# CPSW1_NUSS register map
Vendor: Texas Instruments
Registers are 32-bit, read-write, reset 0x0 unless marked. A register's access mark holds for its fields unless they carry their own. Offsets are as the file gives them; [hi:lo] are bit positions; lines under a group give offsets from that group; {n}, {i} and the like mark numbered series; <NAME> marks a mode.

## CPSW1_NUSS (part 2 of 2)
0x3A2BC CPSW_NUSS_VBUSP_ALE_UNKN_BRD_BCNT — ALE Receive Unknown Broadcast Bytecount
  [31:0] COUNT
0x3A2C0 CPSW_NUSS_VBUSP_ALE_POL_MATCH — ALE Policer Matched
  [31:0] COUNT
0x3A2C4 CPSW_NUSS_VBUSP_ALE_POL_MATCH_RED — ALE Policer Matched and Condition Red
  [31:0] COUNT
0x3A2C8 CPSW_NUSS_VBUSP_ALE_POL_MATCH_YELLOW — ALE Policer Matched and Condition Yellow
  [31:0] COUNT
0x3A2CC CPSW_NUSS_VBUSP_ALE_MULT_SA_DROP — ALE Multicast Source Address Drop
  [31:0] COUNT — ALE Multicast Source Address drop
0x3A2D0 CPSW_NUSS_VBUSP_ALE_DUAL_VLAN_DROP — ALE Dual VLAN Drop
  [31:0] COUNT — ALE Dual VLAN drop
0x3A2D4 CPSW_NUSS_VBUSP_ALE_LEN_ERROR_DROP — ALE Length Error Drop
  [31:0] COUNT — ALE Length Error drop
0x3A2D8 CPSW_NUSS_VBUSP_ALE_IP_NEXT_HDR_DROP — ALE IP Next Header Drop
  [31:0] COUNT — ALE Next Header drop
0x3A2DC CPSW_NUSS_VBUSP_ALE_IPV4_FRAG_DROP — ALE IPV4 Frag Drop
  [31:0] COUNT — ALE IPV4 Fragment drop
0x3A340 CPSW_NUSS_VBUSP_IET_RX_ASSEMBLY_ERROR_REG — IET Receive Assembly Error
  [31:0] IET_RX_ASSEMBLY_ERROR
0x3A344 CPSW_NUSS_VBUSP_IET_RX_ASSEMBLY_OK_REG — IET Receive Assembly Ok
  [31:0] IET_RX_ASSEMBLY_OK
0x3A348 CPSW_NUSS_VBUSP_IET_RX_SMD_ERROR_REG — IET Receive Smd Error
  [31:0] IET_RX_SMD_ERROR
0x3A34C CPSW_NUSS_VBUSP_IET_RX_FRAG_REG — IET Receive Frag
  [31:0] IET_RX_FRAG
0x3A350 CPSW_NUSS_VBUSP_IET_TX_HOLD_REG — IET Transmit Hold
  [31:0] IET_TX_HOLD
0x3A354 CPSW_NUSS_VBUSP_IET_TX_FRAG_REG — IET Transmit Frag
  [31:0] IET_TX_FRAG
0x3A37C CPSW_NUSS_VBUSP_TX_MEMORY_PROTECT_ERROR — Transmit Memory Protect CRC Error
  [7:0] COUNT
0x3A380 CPSW_NUSS_VBUSP_ENET_PN_TX_PRI_REG — ENET Port n PRIORITY N Packet Count
  [31:0] PN_TX_PRIN — Enet Port n Priority N Packet Count
0x3A3A0 CPSW_NUSS_VBUSP_ENET_PN_TX_PRI_BCNT_REG — ENET Port n PRIORITY N Packet Byte Count
  [31:0] PN_TX_PRIN_BCNT
0x3A3C0 CPSW_NUSS_VBUSP_ENET_PN_TX_PRI_DROP_REG — ENET Port n PRIORITY N Packet Drop Count
  [31:0] PN_TX_PRIN_DROP
0x3A3E0 CPSW_NUSS_VBUSP_ENET_PN_TX_PRI_DROP_BCNT_REG — ENET Port n PRIORITY N Packet Drop Byte Count
  [31:0] PN_TX_PRIN_DROP_BCNT
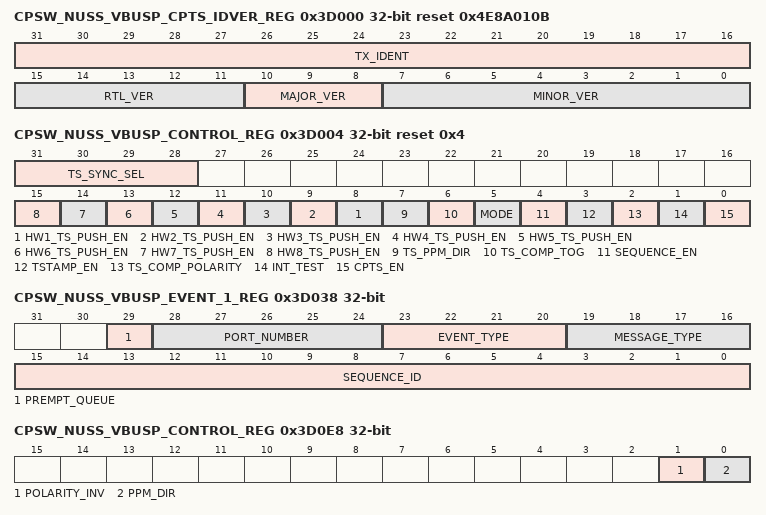
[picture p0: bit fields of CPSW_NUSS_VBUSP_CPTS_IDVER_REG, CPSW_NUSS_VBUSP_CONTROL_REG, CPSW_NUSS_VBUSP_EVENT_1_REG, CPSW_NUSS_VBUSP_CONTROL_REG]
0x3D000 CPSW_NUSS_VBUSP_CPTS_IDVER_REG ro reset 0x4E8A010B — Identification and Version Register
  [31:16] TX_IDENT — Identification value
  [15:11] RTL_VER — RTL version value
  [10:8] MAJOR_VER — Major version value
  [7:0] MINOR_VER — Minor version value
0x3D004 CPSW_NUSS_VBUSP_CONTROL_REG reset 0x4 — Time Sync Control Register
  [31:28] TS_SYNC_SEL — TS_SYNC output timestamp counter bit select
  [n+7] HW{n}_TS_PUSH_EN (n=1..8) — Hardware push {n} enable
  [7] TS_PPM_DIR — Timestamp PPM Direction
  [6] TS_COMP_TOG — Timestamp Compare Toggle mode: 0=TS_COMP is in non-toggle mode, 1=TS_COMP is in toggle mode
  [5] MODE — Timestamp mode
  [4] SEQUENCE_EN — Sequence Enable
  [3] TSTAMP_EN — Host Receive Timestamp Enable
  [2] TS_COMP_POLARITY
  [1] INT_TEST — Interrupt test
  [0] CPTS_EN — Time sync enable
0x3D008 CPSW_NUSS_VBUSP_RFTCLK_SEL_REG — RFTCLK Select Register
  [4:0] RFTCLK_SEL — Reference clock select
0x3D00C CPSW_NUSS_VBUSP_TS_PUSH_REG wo — Time Stamp Event Push Register
  [0] TS_PUSH — Time stamp event push
0x3D010 CPSW_NUSS_VBUSP_TS_LOAD_LOW_VAL_REG — Time Stamp Load Low Value Register
  [31:0] TS_LOAD_VAL — Time stamp load low value
0x3D014 CPSW_NUSS_VBUSP_TS_LOAD_EN_REG wo — Time Stamp Load Enable Register
  [0] TS_LOAD_EN — Time stamp load enable
0x3D018 CPSW_NUSS_VBUSP_TS_COMP_LOW_VAL_REG — Time Stamp Comparison Low Value Register
  [31:0] TS_COMP_VAL — Time stamp comparison low value
0x3D01C CPSW_NUSS_VBUSP_TS_COMP_LEN_REG — Time Stamp Comparison Length Register
  [31:0] TS_COMP_LENGTH — Time stamp comparison length
0x3D020 CPSW_NUSS_VBUSP_INTSTAT_RAW_REG — Interrupt Status Register Raw
  [0] TS_PEND_RAW — TS_PEND_RAW int read (before enable)
0x3D024 CPSW_NUSS_VBUSP_INTSTAT_MASKED_REG ro — Interrupt Status Register Masked
  [0] TS_PEND — TS_PEND masked interrupt read (after enable)
0x3D028 CPSW_NUSS_VBUSP_INT_ENABLE_REG — Interrupt Enable Register
  [0] TS_PEND_EN — TS_PEND masked interrupt enable
0x3D02C CPSW_NUSS_VBUSP_TS_COMP_NUDGE_REG — Time Stamp Comparison Nudge Register
  [7:0] NUDGE — This 2s complement number is added to the ts_comp_length value to increase or decrease the TS_COMP length by the nudge amount
0x3D030 CPSW_NUSS_VBUSP_EVENT_POP_REG wo — Event Pop Register
  [0] EVENT_POP
0x3D034 CPSW_NUSS_VBUSP_EVENT_0_REG ro — Event 0 Register
  [31:0] TIME_STAMP
0x3D038 CPSW_NUSS_VBUSP_EVENT_1_REG ro — Event 1 Register
  [29] PREMPT_QUEUE, [28:24] PORT_NUMBER, [23:20] EVENT_TYPE, [19:16] MESSAGE_TYPE, [15:0] SEQUENCE_ID
0x3D03C CPSW_NUSS_VBUSP_EVENT_2_REG ro — Event 2 Register
  [7:0] DOMAIN
0x3D040 CPSW_NUSS_VBUSP_EVENT_3_REG ro — Event 3 Register
  [31:0] TIME_STAMP
0x3D044 CPSW_NUSS_VBUSP_TS_LOAD_HIGH_VAL_REG — Time Stamp Load High Value Register
  [31:0] TS_LOAD_VAL — Time stamp load high value
0x3D048 CPSW_NUSS_VBUSP_TS_COMP_HIGH_VAL_REG — Time Stamp Comparison High Value Register
  [31:0] TS_COMP_HIGH_VAL — Time stamp comparison high value
0x3D04C CPSW_NUSS_VBUSP_TS_ADD_VAL_REG — TS Add Value Register
  [2:0] ADD_VAL — Add Value
0x3D050 CPSW_NUSS_VBUSP_TS_PPM_LOW_VAL_REG — Time Stamp PPM Low Value Register
  [31:0] TS_PPM_LOW_VAL — Time stamp PPM Low value
0x3D054 CPSW_NUSS_VBUSP_TS_PPM_HIGH_VAL_REG — Time Stamp PPM High Value Register
  [9:0] TS_PPM_HIGH_VAL — Time stamp PPM High value
0x3D058 CPSW_NUSS_VBUSP_TS_NUDGE_VAL_REG — Time Stamp Nudge Value Register
  [7:0] TS_NUDGE_VAL — Time stamp Nudge value
0x3D0E0 CPSW_NUSS_VBUSP_COMP_LOW_REG — Time Stamp Generate Function Comparison Low Value
  [31:0] COMP_LOW
0x3D0E4 CPSW_NUSS_VBUSP_COMP_HIGH_REG — Time Stamp Generate Function Comparison high Value
  [31:0] COMP_HIGH — Time Stamp Generate Function Comparison High Value
0x3D0E8 CPSW_NUSS_VBUSP_CONTROL_REG — Time Stamp Generate Function Control
  [1] POLARITY_INV — Time Stamp Generate Function Polarity Invert
  [0] PPM_DIR — Time Stamp Generate Function PPM Direction
0x3D0EC CPSW_NUSS_VBUSP_LENGTH_REG — Time Stamp Generate Function Length Value
  [31:0] LENGTH
0x3D0F0 CPSW_NUSS_VBUSP_PPM_LOW_REG — Time Stamp Generate Function PPM Low Value
  [31:0] PPM_LOW
0x3D0F4 CPSW_NUSS_VBUSP_PPM_HIGH_REG — Time Stamp Generate Function PPM High Value
  [9:0] PPM_HIGH
0x3D0F8 CPSW_NUSS_VBUSP_NUDGE_REG — Time Stamp Generate Function Nudge Value
  [7:0] NUDGE
0x3D200 CPSW_NUSS_VBUSP_COMP_LOW_REG — Time Stamp ESTF Generate Function Comparison Low Value
  [31:0] COMP_LOW
0x3D204 CPSW_NUSS_VBUSP_COMP_HIGH_REG — Time Stamp ESTF Generate Function Comparison high Value
  [31:0] COMP_HIGH — Time Stamp ESTF Generate Function Comparison High Value
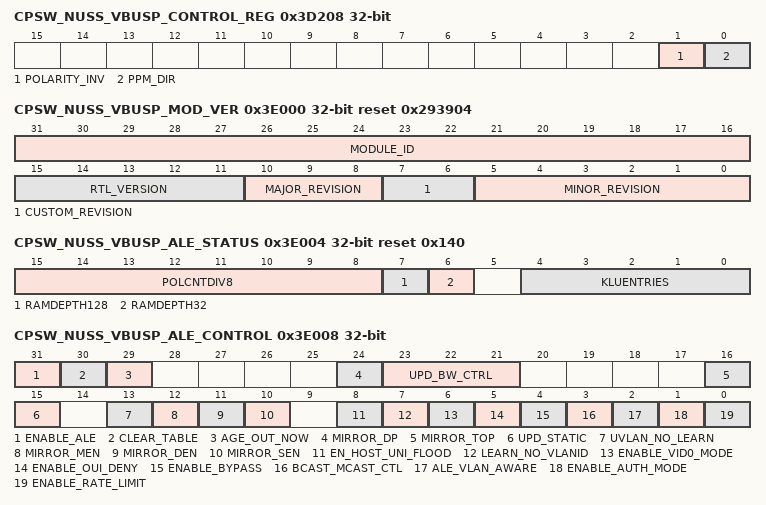
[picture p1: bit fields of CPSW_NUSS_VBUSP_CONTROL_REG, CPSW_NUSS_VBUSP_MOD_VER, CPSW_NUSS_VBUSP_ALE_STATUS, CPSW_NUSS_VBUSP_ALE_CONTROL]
0x3D208 CPSW_NUSS_VBUSP_CONTROL_REG — Time Stamp ESTF Generate Function Control
  [1] POLARITY_INV — Time Stamp ESTF Generate Function Polarity Invert
  [0] PPM_DIR — Time Stamp ESTF Generate Function PPM Direction
0x3D20C CPSW_NUSS_VBUSP_LENGTH_REG — Time Stamp ESTF Generate Function Length Value
  [31:0] LENGTH
0x3D210 CPSW_NUSS_VBUSP_PPM_LOW_REG — Time Stamp ESTF Generate Function PPM Low Value
  [31:0] PPM_LOW
0x3D214 CPSW_NUSS_VBUSP_PPM_HIGH_REG — Time Stamp ESTF Generate Function PPM High Value
  [9:0] PPM_HIGH
0x3D218 CPSW_NUSS_VBUSP_NUDGE_REG — Time Stamp ESTF Generate Function Nudge Value
  [7:0] NUDGE
0x3E000 CPSW_NUSS_VBUSP_MOD_VER ro reset 0x293904 — The Module and Version Register identifies the module identifier and revision of the ALE_2g64i module.
  [31:16] MODULE_ID — ALE_2g64i module ID.
  [15:11] RTL_VERSION
  [10:8] MAJOR_REVISION
  [7:6] CUSTOM_REVISION
  [5:0] MINOR_REVISION
0x3E004 CPSW_NUSS_VBUSP_ALE_STATUS ro reset 0x140 — The ALE status provides information on the ALE configuration and state. The ~iramdepth is used to determine how IPv6 entries are stored in the table. IPv6 entries are stored in two entries where IPv6 Entry hi is designated by the odd slice index and lo is designated by the even slice index. The slice index is above the ram depth like {SlixeIndex,RamIndex}. So for a 64 deep RAM index of 0x005, the Hi portion of the IPv6 entry is located at 0x005|0x040 and the Lo portion is located at 0x005&(~0x040).
  [15:8] POLCNTDIV8 — This is the number of policer engines the ALE implements divided by 8. A value of 4 indicates 32 policer engines total.
  [7] RAMDEPTH128 — The number of ALE entries per slice of the table when this is set it indicates the depth is 128 if both ramdepth128 and ramdepth32 are zero the depth is 64.
  [6] RAMDEPTH32 — The number of ALE entries per slice of the table when this is set it indicates the depth is 32 if both ramdepth128 and ramdepth32 are zero the depth is 64.
  [4:0] KLUENTRIES — This is the number of table entries total divided by 1024. A value of 1 indicates 1024 table entries. A value of 8 indicates 8192 table entries.
0x3E008 CPSW_NUSS_VBUSP_ALE_CONTROL — The ALE Control Register is used to set the ALE modes used for all ports.
  [31] ENABLE_ALE — Enable ALE 0 - Drop all packets 1 - Enable ALE packet processing
  [30] CLEAR_TABLE — Clear ALE address table - Setting this bit causes the ALE hardware to write all table bit values to zero. Software must perform a clear table operation as part of the ALE setup/configuration process. Setting this bit causes all ALE accesses to be held up for 64 clocks while the clear is performed. Access to all ALE registers will be blocked (wait states) until the 64 clocks have completed. This bit cannot be read as one because the read is blocked until the clear table is completed at which time this bit is cleared to zero.
  [29] AGE_OUT_NOW — Age Out Address Table Now - Setting this bit causes the ALE hardware to remove (free up) any ageable table entry that does not have a set touch bit. This bit is cleared when the age out process has completed. This bit may be read. The age out process takes four times the number of table entries clock cycles (4096 cycles for 1K addresses) best case (no ale packet processing during ageout) and sixty five times the number of table entries clock cycles (66560 cycles for 1K addresses) absolute worst case.
  [24] MIRROR_DP — Mirror Destination Port - This field defines the port to which destination traffic destined will be duplicated. That is all traffic that is forwarded to this port will also be mirrored to the ~imirror_top port.
  [23:21] UPD_BW_CTRL — The ~iupd_bw_ctrl field allows for up to 8 times the rate in which adds, updates, touches, writes, and aging updates can occur. At frequencies of 350Mhz, the table update rate should be at it lowest or 5 Million updates per second. When operating the switch core at frequencies or above, the ~iupd_bw_ctrl can be programmed more aggressive. If the ~iupd_bw_ctrl is set but the frequency of the switch subsystem is below the associated value, ALE will drop packets due to insufficient time to complete lookup under high traffic loads. 0 - 350Mhz, 5M 1 - 359Mhz, 11M 2 - 367Mhz, 16M 3 - 375Mhz, 22M 4 - 384Mhz, 28M 5 - 392Mhz, 34M 6 - 400Mhz, 39M 7 - 409Mhz, 45M
  [16] MIRROR_TOP — Mirror To Port - This field defines the destination port for the mirror traffic. If the traffic is received or transmitted on the mirror destination port it will not be duplicated. Traffic defined as mirror traffic only may be dropped by the switch due to congestion.
  [15] UPD_STATIC — Update Static Entries - A static Entry is an entry that is not agable. When clear this bit will prevent any static entry (agable bit clear) from being updated due to port change. When set it allows static entries (agable bit clear) to update the source port if required. This bit should normally be '0' for most switch configurations.
  [13] UVLAN_NO_LEARN — Unknown VLAN No Learn - This field when set will prevent source addresses of unknown VLAN IDs from being automatically added into the look up table if learning is enabled.
  [12] MIRROR_MEN — Mirror Match Entry Enable - This field enables the match mirror option. When this bit is set any traffic whose destination, source, VLAN or OUI matches the ~imirror_midx entry index will have that traffic also sent to the ~imirror_top port.
  [11] MIRROR_DEN — Mirror Destination Port Enable - This field enables the destination port mirror option. When this bit is set any traffic destined for the ~imirror_dp port will have its transmit traffic also sent to the ~imirror_top port.
  [10] MIRROR_SEN — Mirror Source Port Enable - This field enables the source port mirror option. When this bit is set any port with the ~ipX_mirror_sp set in the ALE Port Control registers set will have its received traffic also sent to the ~imirror_top port.
  [8] EN_HOST_UNI_FLOOD — Unknown unicast packets flood to host 0 - unknown unicast packets are not sent to the host 1 - unknown unicast packets flood to host port as well as other ports
  [7] LEARN_NO_VLANID — Learn No VID - 0 - VID is learned with the source address 1 - VID is not learned with the source address (source address is not tied to VID). Determines the entry type.
  [6] ENABLE_VID0_MODE — Enable VLAN ID = 0 Mode 0 - Process the priority tagged packet with VID = PORT_VLAN[11:0]. 1 - Process the priority tagged packet with VID = 0.
  [5] ENABLE_OUI_DENY — Enable OUI Deny Mode - When set, any packet with a non-matching OUI source address will be dropped to the host unless the packet destination address matches a supervisory destination address table entry. When cleared, any packet source address matching an OUI address table entry will be dropped to the host unless the destination address matches with a supervisory destination address table entry.
  [4] ENABLE_BYPASS — ALE Bypass - When set, packets received on non-host ports are sent to the host. It is expected that packets from the host are directed to the particular port. 0 - no bypass 1 - bypass the ALE
  [3] BCAST_MCAST_CTL — Rate Limit Transmit mode 0 - Broadcast and multicast rate limit counters are received port based 1 - Broadcast and multicast rate limit counters are transmit port based
  [2] ALE_VLAN_AWARE — ALE VLAN Aware - Determines how traffic is forwarded using VLAN rules. 0 - Simple switch rules, packets forwarded to all ports for unknown destinations. 1 - VLAN Aware rules, packets forwarded based on VLAN members
  [1] ENABLE_AUTH_MODE — Enable MAC Authorization Mode - Mac authorization mode requires that all table entries be made by the host software. There is no auto learning of addresses in authorization mode and the packet will be dropped if the source address is not found (and the destination address is not a multicast address with the super table entry bit set). 0 - The ALE is not in MAC authorization mode 1 - The ALE is in MAC authorization mode
  [0] ENABLE_RATE_LIMIT — Enable Broadcast and Multicast Rate Limit 0 - Broadcast/Multicast rates not limited 1 - Broadcast/Multicast packet reception limited to the port control register rate limit fields.
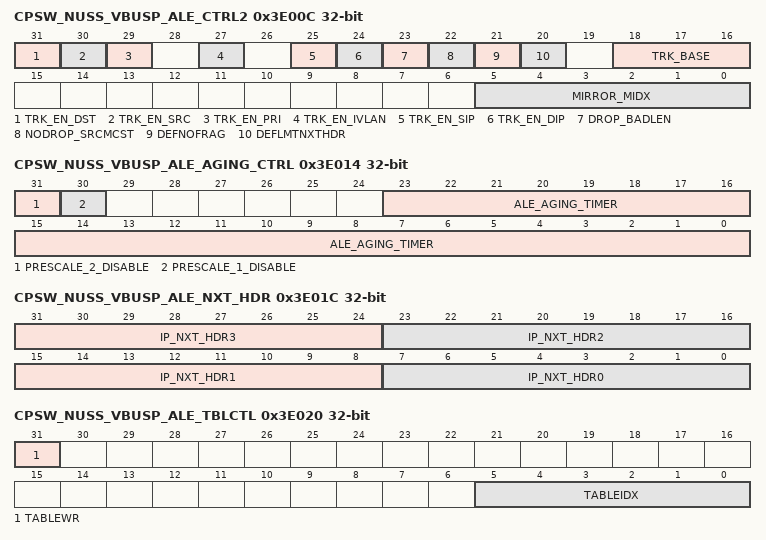
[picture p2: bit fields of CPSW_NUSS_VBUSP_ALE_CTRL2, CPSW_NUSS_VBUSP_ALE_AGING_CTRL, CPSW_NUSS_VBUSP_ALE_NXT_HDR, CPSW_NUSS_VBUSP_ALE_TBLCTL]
0x3E00C CPSW_NUSS_VBUSP_ALE_CTRL2 — The ALE Control 2 Register is used to set the extended features used for all ports.
  [31] TRK_EN_DST — Trunk Enable Destination Address - This field enables the destination MAC address to be used with the hash function G(X) = 1 + X + X^3 and affect the trunk port transmit link determination.
  [30] TRK_EN_SRC — Trunk Enable Source Address - This field enables the source MAC address to be used with the hash function G(X) = 1 + X + X^3 and affect the trunk port transmit link determination.
  [29] TRK_EN_PRI — Trunk Enable Priority - This field enables the VLAN Priority bits to be used with the hash function G(X) = 1 + X + X^3 and affect the trunk port transmit link determination. In the event that DSCP mapping is enabled and there is no VLAN the DSCP priority will be used. For all other non IP frames without VLAN the port default priority is used.
  [27] TRK_EN_IVLAN — Trunk Enable Inner VLAN - This field enables the inner VLAN ID value (C-VLANID) to be used with the hash function G(X) = 1 + X + X^3 and affect the trunk port transmit link determination.
  [25] TRK_EN_SIP — Trunk Enable Source IP Address - This field enables the source IP address to be used with the hash function G(X) = 1 + X + X^3 and affect the trunk port transmit link determination. This feature supports No tag, Priority tagged, VLAN tagged, Q-in-Q double tagging for both IPV6 and IPV4.
  [24] TRK_EN_DIP — Trunk Enable Destination IP Address - This field enables the destination IP address to be used with the hash function G(X) = 1 + X + X^3 and affect the trunk port transmit link determination. This feature supports No tag, Priority tagged, VLAN tagged, Q-in-Q double tagging for both IPV6 and IPV4.
  [23] DROP_BADLEN — Drop Bad Length will drop any packet that the 802.3 length field is larger than the packet. Ethertypes 0-1500 are 802.3 lengths, all others are Ether types.
  [22] NODROP_SRCMCST — No Drop Source Multicast will disable the dropping of any source address with the multicast bit set.
  [21] DEFNOFRAG — Default No Frag field will cause an IPv4 fragmented packet to be dropped if a VLAN entry is not found.
  [20] DEFLMTNXTHDR — Default limit next header field will cause an IPv4 protocol or IPv6 next header packet to be dropped if a VLAN entry is not found and the protocol or next header does not match the ~iALE_NXT_HDR register values.
  [18:16] TRK_BASE — Trunk Base - This field is the hash formula starting value. Changing this value will cause the packet distribution on trunk ports to be changed. If all the ~itrk_en_dst, ~itrk_en_src, ~itrk_en_pri and ~itrk_en_vlan are '0', this value is used as the distribution index. That is a '0' will select the 1st bit of an 'N' link trunk, a '1' will select the second, etc. Below is the distribution across the trunk links. The first number in the ~iitalic sequence indicates the traffic is sent to the lowest numbered port of a trunk group. For example if you have a 3 port trunk, the hash result 0 will go to the base port (0), hash result 1 will go to the highest port of the trunk group (2), hash result 2 will go to the middle port (1), etc. 1 - ~i00000000 2 - ~i01010101 3 - ~i02102102 4 - ~i03210321
  [5:0] MIRROR_MIDX — Mirror Index - This field is the ALE lookup table entry index that when a match occurs will cause this traffic to be mirrored to the ~imirror_top port. That is any VLAN, ONU or address with or withou VLAN can be selected for traffic mirroring.
0x3E010 CPSW_NUSS_VBUSP_ALE_PRESCALE — The ALE Prescale Register is used to set the Broadcast and Multicast rate limiting prescaler value.
  [19:0] ALE_PRESCALE — ALE Prescale - The input clock is divided by this value for use in the multicast/broadcast rate limiters. The minimum operating value is 0x10. The prescaler is off when the value is zero.
0x3E014 CPSW_NUSS_VBUSP_ALE_AGING_CTRL — The ALE Aging Control sets the aging interval which will cause periodic aging to occur. This value specifies the minimum time between aging starts.
  [31] PRESCALE_2_DISABLE — ALE Prescaler 2 Disable - When set will divide the aging interval by 1000. This bit is designed for device verification and should not be used in production software. Combination of PreScale1Disable and PreScale2Disable will divide the aging interval by 1,000,000 for test purposes.
  [30] PRESCALE_1_DISABLE — ALE Prescaler 1 Disable - When set will divide the aging interval by 1000. This bit is designed for device verification and should not be used in production software. Combination of PreScale1Disable and PreScale2Disable will divide the aging interval by 1,000,000 for test purposes.
  [23:0] ALE_AGING_TIMER — ALE Aging Timer - This field specifies the number of clock cycles times 1,000,000 between aging operations.
0x3E01C CPSW_NUSS_VBUSP_ALE_NXT_HDR — The ALE Next Header is used to limit the IPv6 Next header or IPv4 Protocol values found in the IP header. It is enabled via the ~iLmtNxtHdr bit in the VLAN entry. All four ~iip_nxt_hdr0-3 are compared when enabled, so if only one is required, set them all to the one value to be tested.
  [31:24] IP_NXT_HDR3 — The ~iip_nxt_hdr3 is the forth protocol or next header compared when enabled.
  [23:16] IP_NXT_HDR2 — The ~iip_nxt_hdr2 is the third protocol or next header compared when enabled.
  [15:8] IP_NXT_HDR1 — The ~iip_nxt_hdr1 is the second protocol or next header compared when enabled.
  [7:0] IP_NXT_HDR0 — The ~iip_nxt_hdr0 is the first protocol or next header compared when enabled.
0x3E020 CPSW_NUSS_VBUSP_ALE_TBLCTL — The ALE table control register is used to read or write that ALE table entries. After writing to this register any read or write to any ALE register will be stalled until the read or write operation completes.
  [31] TABLEWR — Table Write - This bit is used to write the table words to the lookup table. 0 - Table Read Operation is performed. The contents of the ~b TABLEIDX entry will be read into the ~b ALE_TBLWx registers 1 - Table write operation is performed. This will take the current contents from the ~b ALE_TBLWx registers and write them to the table at the specified ~b TABLEIDX.
  [5:0] TABLEIDX — The table index is used to determine which lookup table entry is read or written.
0x3E034 CPSW_NUSS_VBUSP_ALE_TBLW2 — The ALE Table Word 2 is the most significant word of an ALE table entry.
  [6:0] TABLEWRD2 — Table Entry bits [71:64]
0x3E038 CPSW_NUSS_VBUSP_ALE_TBLW1 — The ALE Table Word 1 is the middle word of an ALE table entry.
  [31:0] TABLEWRD1 — Table Entry bits [63:32]
0x3E03C CPSW_NUSS_VBUSP_ALE_TBLW0 — The ALE Table Word 0 is the least significant word of an ALE table entry.
  [31:0] TABLEWRD0 — Table Entry bits [31:0]
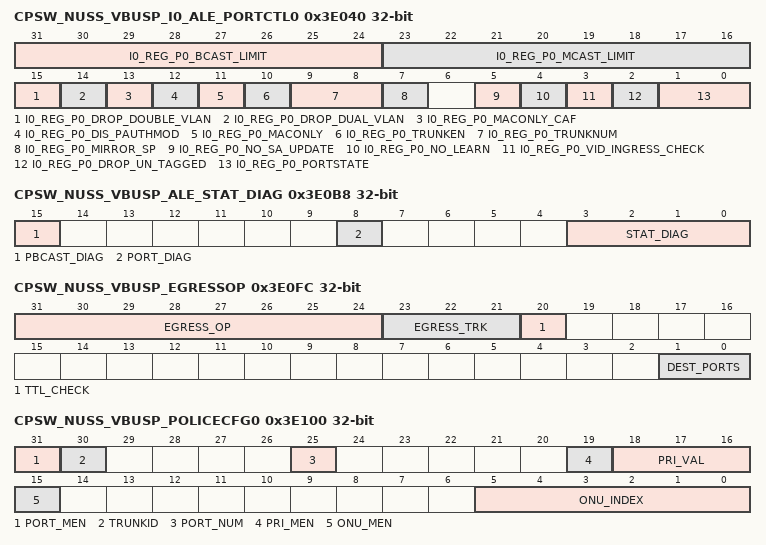
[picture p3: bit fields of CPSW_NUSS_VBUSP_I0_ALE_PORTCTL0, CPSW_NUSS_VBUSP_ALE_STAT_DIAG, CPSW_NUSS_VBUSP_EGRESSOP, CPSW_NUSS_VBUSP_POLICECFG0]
0x3E040 CPSW_NUSS_VBUSP_I0_ALE_PORTCTL0 — The ALE Port Control Register sets the port specific modes of operation.
  [31:24] I0_REG_P0_BCAST_LIMIT — Broadcast Packet Rate Limit - Each prescale pulse loads this field into the port broadcast rate limit counter. The port counters are decremented with each packet received or transmitted depending on whether the mode is transmit or receive. If the counters decrement to zero, then further packets are rate limited until the next prescale pulse. Broadcast rate limiting is enabled by a non-zero value in this field.
  [23:16] I0_REG_P0_MCAST_LIMIT — Multicast Packet Rate Limit - Each prescale pulse loads this field into the port multicast rate limit counter. The port counters are decremented with each packet received or transmitted depending on whether the mode is transmit or receive. If the counters decrement to zero, then further packets are rate limited until the next prescale pulse. Multicast rate limiting is enabled by a non-zero value in this field.The ~imcast_limit is the number of Multicast packets that will be forwaded per ~iale_prescale time.
  [15] I0_REG_P0_DROP_DOUBLE_VLAN — Drop Double VLAN - When set cause any received packet with double VLANs to be dropped. That is if there are two ctag or two stag fields in the packet it will be dropped.
  [14] I0_REG_P0_DROP_DUAL_VLAN — Drop Dual VLAN - When set will cause any received packet with dual VLAN stag followed by ctag to be dropped.
  [13] I0_REG_P0_MACONLY_CAF — Mac Only Copy All Frames - When set a Mac Only port will transfer all received good frames to the host. When clear a Mac Only port will transfer packets to the host based on ALE destination address lookup operation (which operates more like an Ethernet Mac). A Mac Only port is a port with ~imaconly set.
  [12] I0_REG_P0_DIS_PAUTHMOD — Disable Port authorization - When set will allow unknown addresses to arrive on a switch in authorization mode. It is intended for device to device network connection on ports which do not require MACSEC encryption.
  [11] I0_REG_P0_MACONLY — MAC Only - When set enables this port be treated like a MAC port for the host. All traffic received is only sent to the host. The host must direct traffic to this port as the lookup engine will not send traffic to the ports with the ~ip0_maconly bit set and the ~ip0_no_learn also set. If ~ip0_maconly bit is set and the ~ip0_no_learn is not set, the host can send non-directed packets that can be sent to the destination of a MacOnly port. It is also possible that The host can broadcast to all ports including MacOnly ports in this mode.
  [10] I0_REG_P0_TRUNKEN — Trunk Enable - This field is used to enable a port into a trunk. Any port can be used as a trunk port, any two or more ports with the ~ip0_trunken its set and having the same ~ip0_trunknum will be placed in the same trunk. There is no requirement for trunk ports to be adjacent. If all ports are enabled in the same trunk, no traffic can flow as traffic received within a trunk is never trasnmitted out the same trunk. If only a single port is a member of a trunk, it looks like a normal port with exception of entries in the look up table will be noted as a trunk entry.
  [9:8] I0_REG_P0_TRUNKNUM — Trunk Number - This field is used as the trunk number when the ~ip0_trunken is also set. Ports with the same trunk number that have the ~ip0_trunken also set will have traffic distributed within the trunk based on the result of the hash function descrived above.
  [7] I0_REG_P0_MIRROR_SP — Mirror Source Port - This field enables the source port mirror option. When this bit is set any traffic received on the port with the reg_p0_mirror_sp bit set will have its received traffic also sent to the ~imirror_top port.
  [5] I0_REG_P0_NO_SA_UPDATE — No Source Address Update - When set will not update the source addresses for this port.
  [4] I0_REG_P0_NO_LEARN — No Learn - When set will not learn the source addresses for this port.
  [3] I0_REG_P0_VID_INGRESS_CHECK — VLAN Ingress Check - When set if a packet received is not a member of the VLAN, the packet will be dropped.
  [2] I0_REG_P0_DROP_UN_TAGGED — If Drop Untagged - When set will drop packets without a VLAN tag.
  [1:0] I0_REG_P0_PORTSTATE — Port State - Defins the current port state used for lookup operations. 0 - Disabled 1 - Blocked 2 - Learning 3 - Forwarding
0x3E090 CPSW_NUSS_VBUSP_ALE_UVLAN_MEMBER — The ALE Unknown VLAN Member Mask Register is used to specify the member list for unknown VLAN ID.
  [1:0] UVLAN_MEMBER_LIST — Unknown VLAN Member List - Each bit represents the port member status for unknown VLANs.
0x3E094 CPSW_NUSS_VBUSP_ALE_UVLAN_URCAST — The ALE Unknown VLAN Unregistered Multicast Flood Mask Register is used to specify which egress ports unregistered multicast addresses egress for the unregistered VLAN ID.
  [1:0] UVLAN_UNREG_MCAST_FLOOD_MASK — Unknown VLAN Unregister Multicast Flood Mask - Each bit represents the port to which unregistered multicast are sent for unregistered VLANs.
0x3E098 CPSW_NUSS_VBUSP_ALE_UVLAN_RMCAST — The ALE Unknown VLAN Registered Multicast Flood Mask Register is used to specify which egress ports registered multicast addresses egress for the unregistered VLAN ID.
  [1:0] UVLAN_REG_MCAST_FLOOD_MASK — Unknown VLAN Register Multicast Flood Mask - Each bit represents the port to which registered multicast are sent for unregistered VLANs. This field is ANDed with the registered multicast mask to determine the destinations for unregistered VLANs.
0x3E09C CPSW_NUSS_VBUSP_ALE_UVLAN_UNTAG — The ALE Unknown VLAN force Untagged Egress Mask Register is used to specify which egress ports the VLAN ID will be removed.
  [1:0] UVLAN_FORCE_UNTAGGED_EGRESS — Unknown VLAN Force Untagged Egress Mask - Each bit represents the port where the VLAN will be removed for unregistered VLANs.
0x3E0B8 CPSW_NUSS_VBUSP_ALE_STAT_DIAG — The ALE Statistic Output Diagnostic Register allows the output statistics to diagnose the SW counters. This register is for diagnostice only.
  [15] PBCAST_DIAG — When set and the ~iport_diag is set to zero, will allow all ports to see the same stat diagnostic increment.
  [8] PORT_DIAG — The port selected that a received packet will cause the selected error to increment
  [3:0] STAT_DIAG — When non-zero will cause the selected statistic to increment on the next frame received. For the selected Port. 0: Disabled 1: Destination Equal Source Drop Stat will count 2: VLAN Ingress Check Drop Stat will count 3: Source Multicast Drop Stat will count 4: Dual VLAN Drop Stat will count 5: Ether Type length error Drop Stat will count 6: Next Hop Limit Drop Stat will count 7: IPv4 Fragment Drop Stat will count 8: Classifier Hit Stat will count 9: Classifier Red Drop Stat will count 10: Classifier Yellow Drop Stat will count 11: ALE Overflow Drop Stat will count 12: Rate Limit Drop Stat will count 13: Blocked Address Drop Stat will count 14: Secure Address Drop Stat will count 15: Authorization Drop Stat will count
0x3E0BC CPSW_NUSS_VBUSP_ALE_OAM_LB_CTRL — The ALE OAM Control allows ports to be put into OAM Loopback, only non-supervisor packet are looped back to the source port.
  [1:0] OAM_LB_CTRL — The ~ioam_lb_ctrl allows any port to be put into OAM loopback, that is any packet received will be returned to the same port with an egressop of 0xFF which swaps the source and destination address. BPDUs will still flow through as normal so that OAM can be remotly requested and disabled.
0x3E0C0 CPSW_NUSS_VBUSP_ALE_MSK_MUX0 ro reset 0x3 — VLAN Mask Mux x - The ALE Mask Mux registers are used along with the VLAN registered/unregistered index selectors from the Lookup Table to determine the value for vlan registered and unregister mask respectively.
  [1:0] VLAN_MASK_MUX_0 — VLAN Mask Mux x - When selected by the VLAN lookup table entry FwdUnRegIdx or FwdAllRegIdx is used as the FwdUnRegMask or FwdUnRegMask values anded with the member list to determine the forwarding of packets. The Value of vlan_mask_mux_0 is read only and set to all ones for all ports.
0x3E0C4 CPSW_NUSS_VBUSP_I1_ALE_MSK_MUX1 — VLAN Mask Mux x - The ALE Mask Mux registers are used along with the VLAN registered/unregistered index selectors from the Lookup Table to determine the value for vlan registered and unregister mask respectively.
  [1:0] I1_REG_VLAN_MASK_MUX_1 — VLAN Mask Mux x - When selected by the VLAN lookup table entry FwdUnRegIdx or FwdAllRegIdx is used as the FwdUnRegMask or FwdUnRegMask values anded with the member list to determine the forwarding of packets. The Value of vlan_mask_mux_0 is read only and set to all ones for all ports.
0x3E0FC CPSW_NUSS_VBUSP_EGRESSOP — The Egress Operation register allows enabled classifiers with IPSA or IPDA match to use the CPSW Egress Packet Operations Inter VLAN Routing sub functions. If the packet was destined for the host, but matches a clasifier that has a programmed egress opcode, it will be forwarded to the destination ports where the destination ports will use the thier egress opcode entry to modify the packet. InterVLAN Routing and mirroring need to be understood, they are orthogonal functions.
  [31:24] EGRESS_OP — The Egress Operation defines the operation performed by the CPSW Egress Packet Operations 0: NOP : 1-n: Defines which egress Operation will be performed. This allows Inter VLAN routing to be configured for high bandwidth traffic, reducing CPU load. 0xff: Swap SA and DA of packet, this is intended to allow OAM diagnostics for a link.
  [23:21] EGRESS_TRK — The Egress Trunk Index is the calculated trunk index from the SA, DA or VLAN if modified to that InterVLAN routing will work on trunks as well. The DA, SA and VLAN are ignored for trunk generation on InterVLAN Routing so that this field is the index generated from the Egress Op replacements elclusive or'd together into a three bit index.
  [20] TTL_CHECK — The TTL Check will cause any packet that fails TTL checks to not be routed to the Inter VLAN Routing sub functions. The packet will be routed to the host it was destined to.
  [1:0] DEST_PORTS — The Destination Ports is a list of the ports the classified packet will be set to. If a destination is a Trunk, all the port bits for that trunck must be set.
0x3E100 CPSW_NUSS_VBUSP_POLICECFG0 — The Policing Config 0 holds the port, frame priority and ONU address index as well as match enables for port, frame priority and ONU address matching.
  [31] PORT_MEN — Port Match Enable - Enabled port match for the selected policing/classifier entry
  [30] TRUNKID — Trunk ID - When set indicates the port number is a trunk group.
  [25] PORT_NUM — Port Number - Specifies the port address to match for the selected policing/classifier entry
  [19] PRI_MEN — Priority Match Enable - Enables frame priority match for the selected policing/classifier entry
  [18:16] PRI_VAL — Priority Value - Specifies the frame priority to match for the selected policing/classifier entry
  [15] ONU_MEN — OUI Match Enable - Enables frame ONU address match for the selected policing/classifier entry
  [5:0] ONU_INDEX — OUI Table Entry Index - Specifies the ALE ONU address lookup table index to match for the selected policing/classifier entry
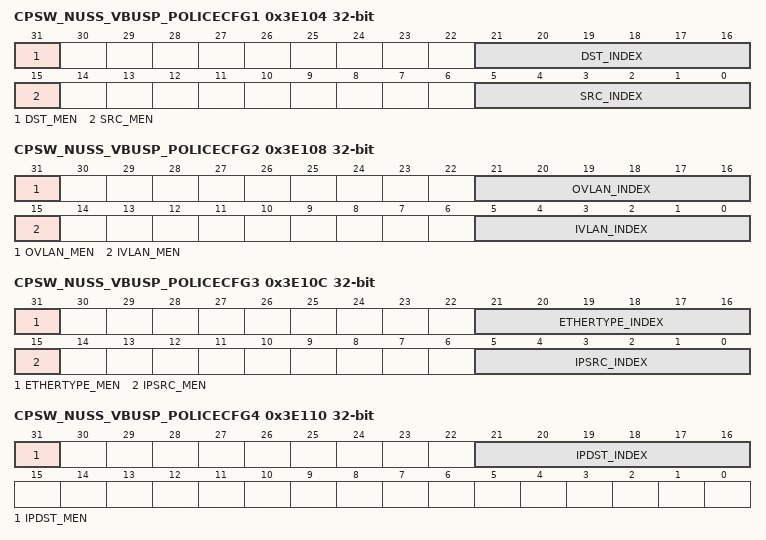
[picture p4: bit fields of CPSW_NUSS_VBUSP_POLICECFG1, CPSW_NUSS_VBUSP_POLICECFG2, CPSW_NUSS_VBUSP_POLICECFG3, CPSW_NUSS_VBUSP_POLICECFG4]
0x3E104 CPSW_NUSS_VBUSP_POLICECFG1 — The Policing Config 1 holds the match enable/match index for the L2 Destination and L2 source addresses
  [31] DST_MEN — Destination Address Match Enable - Enables frame L2 destination address match for the selected policing/classifier entry
  [21:16] DST_INDEX — Destination Address Table Entry Index - Specifies the ALE L2 destination address lookup table index to match for the selected policing/classifier entry
  [15] SRC_MEN — Source Address Match Enable - Enables frame L2 source address match for the selected policing/classifier entry
  [5:0] SRC_INDEX — Source Address Table Entry Index - Specifies the ALE L2 source address lookup table index to match for the selected policing/classifier entry
0x3E108 CPSW_NUSS_VBUSP_POLICECFG2 — The Policing Config 2 holds the match enable/match index for the Outer VLAN and Inner VLAN addresses
  [31] OVLAN_MEN — Outer VLAN Match Enable - Enables frame Outer VLAN address match for the selected policing/classifier entry
  [21:16] OVLAN_INDEX — Outer VLAN Table Entry Index - Specifies the ALE Outer VLAN address lookup table index to match for the selected policing/classifier entry
  [15] IVLAN_MEN — Inner VLAN Match Enable - Enables frame Inner VLAN address match for the selected policing/classifier entry
  [5:0] IVLAN_INDEX — Inner VLAN Table Entry Index - Specifies the ALE Inner VLAN address lookup table index to match for the selected policing/classifier entry
0x3E10C CPSW_NUSS_VBUSP_POLICECFG3 — The Policing Config 3 holds the match enable/match index for the Ether Type and IP Source address
  [31] ETHERTYPE_MEN — EtherType Match Enable - Enables frame Ether Type match for the selected policing/classifier entry
  [21:16] ETHERTYPE_INDEX — EtherType Table Entry Index - Specifies the ALE Ether Type lookup table index to match for the selected policing/classifier entry
  [15] IPSRC_MEN — IP Source Address Match Enable - Enables frame IP Source address match for the selected policing/classifier entry
  [5:0] IPSRC_INDEX — IP Source Address Table Entry Index - Specifies the ALE IP Source address lookup table index to match for the selected policing/classifier entry
0x3E110 CPSW_NUSS_VBUSP_POLICECFG4 — The Policing Config 4 holds the match enable/match index for the IP Destination address
  [31] IPDST_MEN — IP Destination Address Match Enable - Enables frame IP Destination address match for the selected policing/classifier entry
  [21:16] IPDST_INDEX — IP Destination Address Table Entry Index - Specifies the ALE IP Destination address lookup table index to match for the selected policing/classifier entry
0x3E118 CPSW_NUSS_VBUSP_POLICECFG6 — The PIR counter is a 37 bit internal counter where ~ipir_idle_inc_val is added every clock and the frame size << 18 is subtracted at EOF if not RED at LUT time. If the counter is negative the packet will be marked RED, else it can be YELLOW or GREEN based on the CIR counter. If only this counter is used (aka cir_idle_inc_val==0) Packet are marked RED or GREEN based on PIR counter only.
  [31:0] PIR_IDLE_INC_VAL — Peak Information Rate Idle Increment Value - The number added to the PIR counter every clock cycle. If zero the PIR counter is disabled and packets will never be marked or processed as RED.
0x3E11C CPSW_NUSS_VBUSP_POLICECFG7 — The CIR counter is a 37 bit internal counter where ~icir_idle_inc_val is added every clock and the frame size << 18 is subtracted at EOF if not RED or YELLOW at LUT time. If the counter is positive the packet will be marked GREEN, else it can be YELLOW or RED based on the PIR counter. If only this counter is used (aka pir_idle_inc_val==0) Packet are marked YELLOW or GREEN based on CIR counter only.
  [31:0] CIR_IDLE_INC_VAL — Committed Information Idle Increment Value - The number added to the CIR counter every clock cycle. If zero the CIR counter is disabled and packets will never be marked or processed as YELLOW.
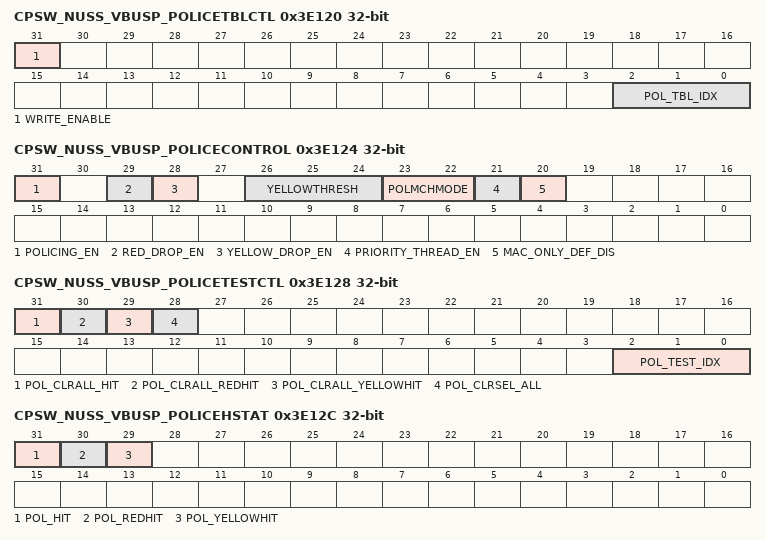
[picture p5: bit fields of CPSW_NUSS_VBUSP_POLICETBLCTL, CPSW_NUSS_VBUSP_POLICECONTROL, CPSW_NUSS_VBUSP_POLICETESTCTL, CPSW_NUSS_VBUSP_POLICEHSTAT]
0x3E120 CPSW_NUSS_VBUSP_POLICETBLCTL — The Policing Table Control is used to read or write the selected policing/classifier entry. The selected policing/classifier entry is only read or written after this register is written based on the value of the ~iwrite_enable bit.
  [31] WRITE_ENABLE — Write Enable - Setting this bit will write the POLICECFG0-7 to the ~ipol_tbl_idx selected policing/classifier entry. Clearing this bit will read the ~ipol_tbl_idx selected policing/classifier entry into the POLICECFG0-7 registers.
  [2:0] POL_TBL_IDX — Policer Entry Index - This field specifies the policing/classifier entry to be read or written. When writing to this field without setting the ~iwrite_enable=1 will cause the selected policing/classifier entry to be loaded into the POLICECFG0-7 registers. When writing to this field with setting the ~iwrite_enable=1 will cause the selected policing/classifier entry to be updated from the POLICECFG0-7 registers.
0x3E124 CPSW_NUSS_VBUSP_POLICECONTROL — The Control Enables color marking as well as internal ALE packet dropping rules.
  [31] POLICING_EN — Policing Enable - Enables the policing to color the packets, this also enables red or yellow drop capabilities.
  [29] RED_DROP_EN — RED Drop Enable - Enables the ALE to drop the red colored packets.
  [28] YELLOW_DROP_EN — WELLOW Drop Enable - Enables the ALE to drop yellow packets based on the ~iyellowthresh value. This field would normally not be used as to let the switch drop packets at a buffer threshold instead. In the event that the switch does not enable buffer threshold dropping, YELLOW packets can be dropped based on this feature.
  [26:24] YELLOWTHRESH — Yellow Threshold - When set enables a portion of the yellow packets to be dropped based on the ~iyellow_drop_en enable. 0-100% 1=50% 2-33% 3-25% 4=20% 5-17% 6-14% 7-13%
  [23:22] POLMCHMODE — Policing Match Mode - This field determines what happens to packets that fail to hit any policing/classifier entry. 0 - No Hit packets are marked GREEN 1 - No Hit packets are marked YELLOW 2 - No Hit packets are marked RED 3 - No Hit packets are marked based on policing/classifier entry=0 state.
  [21] PRIORITY_THREAD_EN — Priority Thread Enable - This field determines if priority is OR'd to the default thread when no classifiers hit and the default thread is enabled.
  [20] MAC_ONLY_DEF_DIS — MAC Only Default Disable - This field when set disables the default thread on MAC Only Ports. That is the default thread will be {port,priority}. If the traffic matches a classifier with a thread mapping, the classifier thread mapping still occurs.
0x3E128 CPSW_NUSS_VBUSP_POLICETESTCTL — The Policing Test Control enables the ability to determine which policing entry has been hit and whether they reported a red or yellow rate condition.
  [31] POL_CLRALL_HIT — Policer Clear - This bit clears all the policing/classifier hit bits. This bit is self clearing. This can be used to test the fact that a policing/classifier entry has been hit.
  [30] POL_CLRALL_REDHIT — Policer Clear RED - This bit clears all the policing/classifier RED hit bits. This bit is self clearing. This can be used to test the fact that a policing/classifier entry has been hit during a RED condition.
  [29] POL_CLRALL_YELLOWHIT — Policer Clear YELLOW - This bit clears all the policing/classifier YELLOW hit bits. This bit is self clearing. This can be used to test the fact that a policing/classifier entry has been hit during a YELLOW condition.
  [28] POL_CLRSEL_ALL — Police Clear Selected - This bit clears the selected policing/classifier hit, redhit and yellowhit bits. This bit is self clearing.
  [2:0] POL_TEST_IDX — Policer Test Index - This field selects which policing/classifier hit bits will be read or written.
0x3E12C CPSW_NUSS_VBUSP_POLICEHSTAT ro — The policing hit status is a read only register that reads the hit bits of the selected policing/classifier.
  [31] POL_HIT — Policer Hit - This indicates that the selected policing/classifier via the ~ipol_test_idx field has been hit by a packet seen on any port that matches the policing/classifier entry match.
  [30] POL_REDHIT — Policer Hit RED - This indicates that the selected policing/classifier via the ~ipol_test_idx field has been hit during a RED condition by a packet seen on any port that matches the policing/classifier entry match.
  [29] POL_YELLOWHIT — Policer Hit YELLOW - This indicates that the selected policing/classifier via the ~ipol_test_idx field has been hit during a YELLOW condition by a packet seen on any port that matches the policing/classifier entry match.
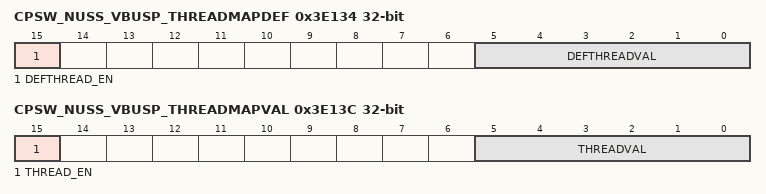
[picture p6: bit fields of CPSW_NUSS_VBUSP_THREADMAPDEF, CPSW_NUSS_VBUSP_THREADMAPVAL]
0x3E134 CPSW_NUSS_VBUSP_THREADMAPDEF — The THREAD Mapping Default Value register is used to set the default thread ID when no classifier is matched,
  [15] DEFTHREAD_EN — Default Tread Enable - When set the switch will use the ~idefthreadval for the host interface thread ID if no classifier is matched. If clear the switch will generate its own thread ID based on port and priority if there is no classifier match.
  [5:0] DEFTHREADVAL — Default Thread Value - This field specifies the default thread ID value.
0x3E138 CPSW_NUSS_VBUSP_THREADMAPCTL — The THREAD Mapping Control register allows the highest matched classifier to return a particular thread ID for traffic sent to the host. This allows particular classifier matched traffic to be placed an a particular hosts queue.
  [2:0] CLASSINDEX — Classifier Index - This is the classifier index entry that the thread enable and thread value will be read or written by the ~bTHREADMAPVAL register.
0x3E13C CPSW_NUSS_VBUSP_THREADMAPVAL — The THREAD Mapping Value register is used to set the thread ID for a particular classifier entry.
  [15] THREAD_EN — Thread Enable - When set the switch will use the ~ithreadval for the selected classifier match. If clear the the thread ID will be determined by the ~bTHREADMAPDEF register settings.
  [5:0] THREADVAL — Thread Value - This field is the thread ID value that is used to map a classifier hit to thread ID for host traffic.
